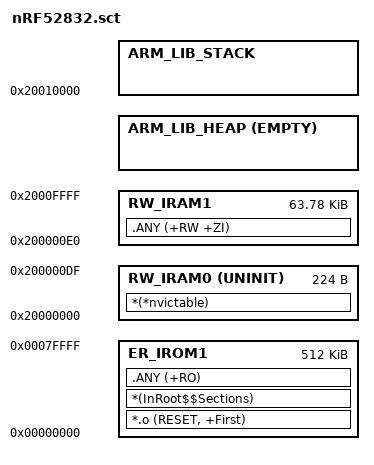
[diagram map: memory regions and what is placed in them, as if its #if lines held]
#! armclang -E --target=arm-arm-none-eabi -x c -mcpu=cortex-m4

/* Default to no softdevice */
#if !defined(MBED_APP_START)
  #define MBED_APP_START 0x0
#endif

#if !defined(MBED_APP_SIZE)
  #define MBED_APP_SIZE 0x80000
#endif

#if !defined(MBED_RAM_START)
  #define MBED_RAM_START 0x20000000
  #define MBED_RAM_SIZE 0x10000
#endif

#if !defined(MBED_CONF_TARGET_BOOT_STACK_SIZE)
#  if defined(MBED_BOOT_STACK_SIZE)
#    define MBED_CONF_TARGET_BOOT_STACK_SIZE MBED_BOOT_STACK_SIZE
#  else
#    define MBED_CONF_TARGET_BOOT_STACK_SIZE 0x800
#  endif
#endif

#define Stack_Size MBED_CONF_TARGET_BOOT_STACK_SIZE

#define MBED_RAM0_START MBED_RAM_START
#define MBED_RAM0_SIZE  0xE0
#define MBED_RAM1_START (MBED_RAM0_START + MBED_RAM0_SIZE)
#define MBED_RAM1_SIZE  (MBED_RAM_SIZE - MBED_RAM0_SIZE)

LR_IROM1 MBED_APP_START MBED_APP_SIZE {
  ER_IROM1 MBED_APP_START MBED_APP_SIZE {
   *.o (RESET, +First)
   *(InRoot$$Sections)
   .ANY (+RO)
  }
  RW_IRAM0 MBED_RAM0_START UNINIT MBED_RAM0_SIZE { ;no init section
        *(*nvictable)
  }
  RW_IRAM1 MBED_RAM1_START MBED_RAM1_SIZE {
   .ANY (+RW +ZI)
  }
  ARM_LIB_HEAP AlignExpr(+0, 16) EMPTY (MBED_RAM1_START + MBED_RAM1_SIZE - MBED_CONF_TARGET_BOOT_STACK_SIZE - AlignExpr(ImageLimit(RW_IRAM1), 16)) {
  }
  ARM_LIB_STACK MBED_RAM1_START + MBED_RAM1_SIZE EMPTY - Stack_Size { ; Stack region growing down
  }
}
